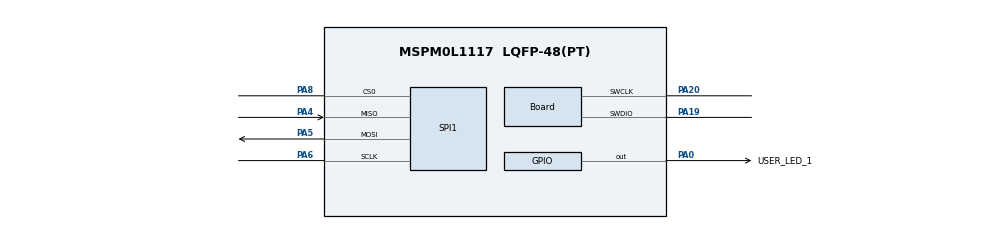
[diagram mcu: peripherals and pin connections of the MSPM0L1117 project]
//@cliArgs --device "MSPM0L111X" --package "LQFP-48(PT)" --part "Default"
//@v2CliArgs --device "MSPM0L1117" --package "LQFP-48(PT)"
// @cliArgs --board /ti/boards/LP_MSPM0L1117 --rtos nortos

/**
 * Import the modules used in this configuration.
 */
const ADC12  = scripting.addModule("/ti/driverlib/ADC12", {}, false);
const ADC121 = ADC12.addInstance();
const GPIO   = scripting.addModule("/ti/driverlib/GPIO", {}, false);
const GPIO1  = GPIO.addInstance();
const SPI    = scripting.addModule("/ti/driverlib/SPI", {}, false);
const SPI1   = SPI.addInstance();

/**
 * Write custom configuration values to the imported modules.
 */
ADC121.$name                      = "ADC12_0";
ADC121.sampClkSrc                 = "DL_ADC12_CLOCK_ULPCLK";
ADC121.sampleTime0                = "125 us";
ADC121.adcMem0chansel             = "DL_ADC12_INPUT_CHAN_2";
ADC121.enabledInterrupts          = ["DL_ADC12_INTERRUPT_MEM0_RESULT_LOADED"];
ADC121.sampClkDiv                 = "DL_ADC12_CLOCK_DIVIDE_8";
ADC121.peripheral.$assign         = "ADC0";
ADC121.peripheral.adcPin2.$assign = "PA25";

const Board                       = scripting.addModule("/ti/driverlib/Board", {}, false);
Board.peripheral.$assign          = "DEBUGSS";
Board.peripheral.swclkPin.$assign = "PA20";
Board.peripheral.swdioPin.$assign = "PA19";

GPIO1.$name                         = "GPIO_LEDS";
GPIO1.associatedPins[0].$name       = "USER_LED_1";
GPIO1.associatedPins[0].pin.$assign = "PA0";

SPI1.$name                              = "SPI_0";
SPI1.mode                               = "PERIPHERAL";
SPI1.rxFifoThreshold                    = "DL_SPI_RX_FIFO_LEVEL_ONE_FRAME";
SPI1.txFifoThreshold                    = "DL_SPI_TX_FIFO_LEVEL_3_4_EMPTY";
SPI1.enabledInterrupts                  = ["RX"];
SPI1.dataSize                           = 16;
SPI1.peripheral.$assign                 = "SPI0";
SPI1.peripheral.sclkPin.$assign         = "PA6";
SPI1.peripheral.mosiPin.$assign         = "PA5";
SPI1.peripheral.misoPin.$assign         = "PA4";
SPI1.peripheral.cs0Pin.$assign          = "PA8";

const SYSCTL              = scripting.addModule("/ti/driverlib/SYSCTL", {}, false);
SYSCTL.peripheral.$assign = "SYSCTL";

const ProjectConfig              = scripting.addModule("/ti/project_config/ProjectConfig", {}, false);
ProjectConfig.migrationCondition = true;
